VERSION ""

NS_ :

BS_:

BU_: XXX

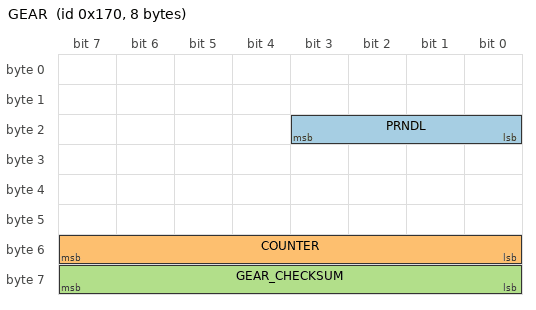
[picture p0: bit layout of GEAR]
BO_ 368 GEAR: 8 XXX
 SG_ PRNDL : 19|4@0+ (1,0) [0|15] "" XXX
 SG_ COUNTER : 55|8@0+ (1,0) [0|255] "" XXX
 SG_ GEAR_CHECKSUM : 63|8@0+ (1,0) [0|255] "" XXX

CM_ SG_ 368 PRNDL "4 = D, 2 = R, 0 = P, E = N, 3 = S (L)";
